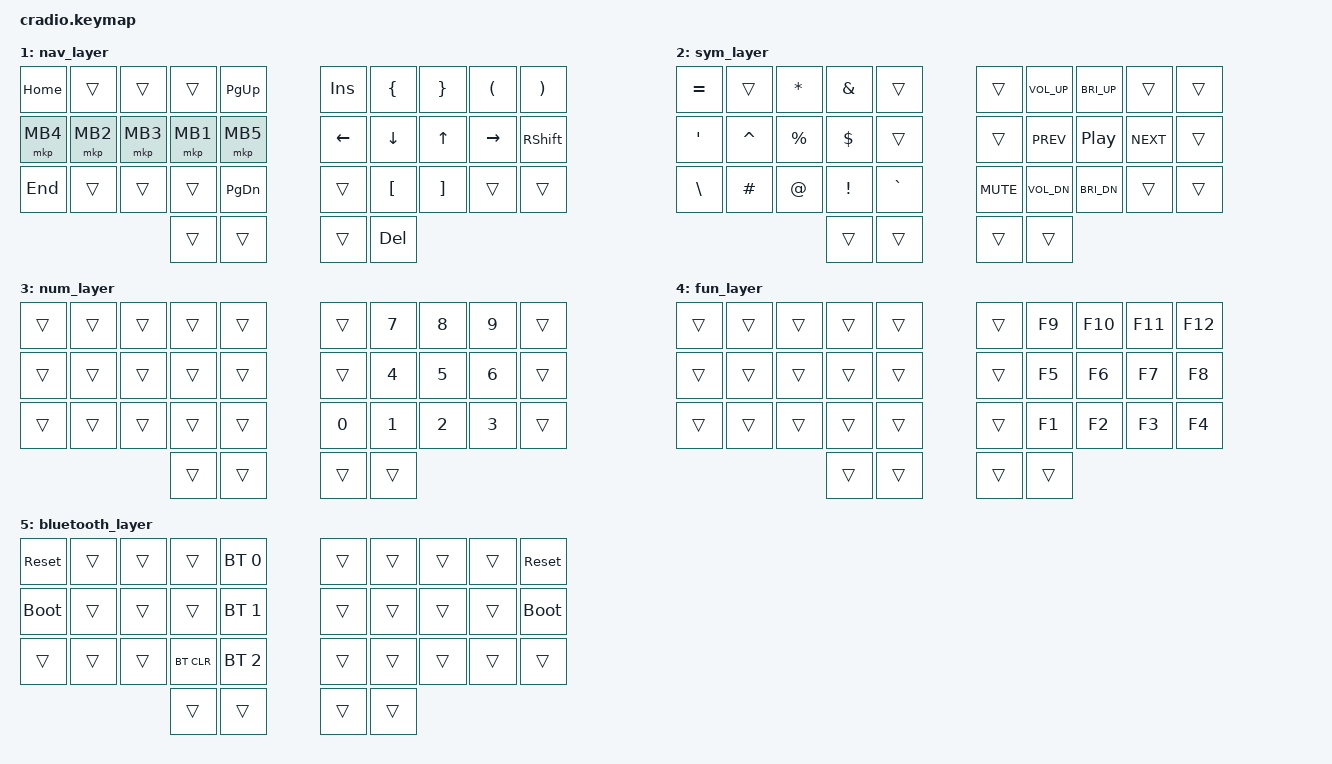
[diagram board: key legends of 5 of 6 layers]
// Copyright (c) 2022 The ZMK Contributors
// SPDX-License-Identifier: MIT

#include <behaviors.dtsi>
#include <dt-bindings/zmk/keys.h>
#include <dt-bindings/zmk/bt.h>
#include <dt-bindings/zmk/mouse.h>

// Define layers
#define COLEMAKDH 0
#define NAV 1
#define SYM 2
#define NUM 3
#define FUN 4
#define BT 5

// Home row mods macro
#define HRML(k1,k2,k3,k4) &ht LSHFT k1  &ht LCTRL k2  &ht LALT k3  &ht LGUI k4
#define HRMR(k1,k2,k3,k4) &ht RGUI k1  &ht RALT k2  &ht RCTRL k3  &ht RSHFT k4

/ {
    behaviors {
        ht: hold_tap {
            compatible = "zmk,behavior-hold-tap";
            #binding-cells = <2>;
            flavor = "tap-preferred";
            tapping-term-ms = <220>;
            quick-tap-ms = <150>;
            require-prior-idle-ms = <100>;
            bindings = <&kp>, <&kp>;
        };
    };
    
    contitional_layers {
        compatible = "zmk,conditional-layers"; 
        bluetooth_layer {
            if-layers = <NAV SYM>;
            then-layer = <BT>;
        };
    };

    combos {
        compatible = "zmk,combos";
        combo_esc {
            timeout-ms = <50>;
            key-positions = <10 19>;
            bindings = <&kp ESC>;
        };
        combo_minus {
            timeout-ms = <50>;
            key-positions = <14 15>;
            bindings = <&kp MINUS>;
        };
        combo_underscore {
            timeout-ms = <50>;
            key-positions = <24 25>;
            bindings = <&kp UNDER>;
        };
        combo_capsword {
            timeout-ms = <50>;
            key-positions = <20 29>;
            bindings = <&caps_word>;
        };
    };

    keymap {
        compatible = "zmk,keymap";
        default_layer {
            bindings = <
            &kp Q   &kp W   &kp F   &kp P   &kp B       &kp J   &kp L   &kp U   &kp Y   &kp SEMI
            HRML(A,   R,      S,      T)    &kp G       &kp M   HRMR(N,   E,      I,      O)
            &kp Z   &kp X   &kp C   &kp D   &kp V       &kp K   &kp H   &kp COMMA   &kp DOT &kp FSLH
                        &lt NUM TAB &lt NAV ENTER       &lt SYM SPACE &lt FUN BSPC
            >;
        };

        nav_layer {
            bindings = <
            &kp HOME   &trans     &trans     &trans     &kp PG_UP       &kp INS   &kp LBRC   &kp RBRC   &kp LPAR    &kp RPAR
            &mkp MB4   &mkp MB2   &mkp MB3   &mkp MB1   &mkp MB5       &kp LEFT   &kp DOWN   &kp UP     &kp RIGHT   &kp RSHFT
            &kp END     &trans     &trans     &trans    &kp PG_DN       &trans     &kp LBKT   &kp RBKT   &trans     &trans
                                             &trans     &trans         &trans     &kp DEL
            >;
        };

        sym_layer {
            bindings = <
            &kp EQUAL   &trans    &kp ASTRK   &kp AMPS   &trans        &trans   &kp C_VOL_UP &kp C_BRI_UP &trans     &trans
            &kp SQT   &kp CARET   &kp PRCNT   &kp DLLR   &trans        &trans    &kp C_PREV  &kp C_PP   &kp C_NEXT   &trans
            &kp BSLH   &kp HASH   &kp AT      &kp EXCL   &kp GRAVE    &kp C_MUTE &kp C_VOL_DN &kp C_BRI_DN  &trans   &trans
                                             &trans     &trans         &trans     &trans
            >;
        };

        num_layer {
            bindings = <
            &trans     &trans     &trans     &trans     &trans         &trans     &kp N7    &kp N8     &kp N9      &trans
            &trans     &trans     &trans     &trans     &trans         &trans     &kp N4     &kp N5     &kp N6     &trans
            &trans     &trans     &trans     &trans     &trans         &kp N0     &kp N1     &kp N2     &kp N3     &trans
                                             &trans     &trans         &trans     &trans
            >;
        };

        fun_layer {
            bindings = <
                &trans  &trans  &trans  &trans  &trans      &trans  &kp F9  &kp F10 &kp F11 &kp F12    
                &trans  &trans  &trans  &trans  &trans      &trans  &kp F5  &kp F6  &kp F7  &kp F8
                &trans  &trans  &trans  &trans  &trans      &trans  &kp F1  &kp F2  &kp F3  &kp F4
                                        &trans  &trans      &trans  &trans
            >;
        };

        bluetooth_layer {
            bindings = <
                &sys_reset  &trans  &trans  &trans  &bt BT_SEL 0        &trans  &trans  &trans  &trans  &sys_reset 
                &bootloader &trans  &trans  &trans  &bt BT_SEL 1        &trans  &trans  &trans  &trans  &bootloader
                &trans  &trans  &trans  &bt BT_CLR  &bt BT_SEL 2        &trans  &trans  &trans  &trans  &trans
                                        &trans  &trans                  &trans  &trans
            >;
        };
    };
};

